# STM32G031C4T6 register map
File version: 1.0
Registers are 32-bit, access not given, reset 0x0 unless marked. A register's access mark holds for its fields unless they carry their own. Offsets are from the block's base; [hi:lo] are bit positions; {n}, {i} and the like mark numbered series.

## I2C1
Base 0x40005400
Same registers: I2C2 0x40005800, I2C3 0x40008800
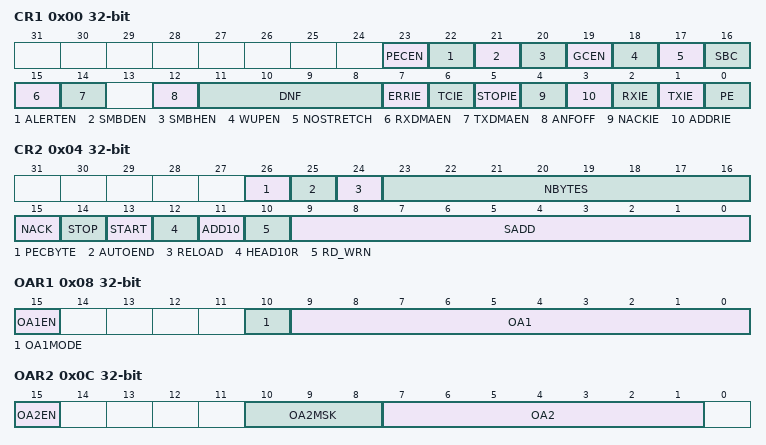
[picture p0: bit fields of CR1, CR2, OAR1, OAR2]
0x00 CR1
  [23] PECEN, [22] ALERTEN, [21] SMBDEN, [20] SMBHEN, [19] GCEN, [18] WUPEN, [17] NOSTRETCH, [16] SBC, [15] RXDMAEN, [14] TXDMAEN, [12] ANFOFF, [11:8] DNF, [7] ERRIE, [6] TCIE, [5] STOPIE, [4] NACKIE, [3] ADDRIE, [2] RXIE, [1] TXIE, [0] PE
0x04 CR2
  [26] PECBYTE, [25] AUTOEND, [24] RELOAD, [23:16] NBYTES, [15] NACK, [14] STOP, [13] START, [12] HEAD10R, [11] ADD10, [10] RD_WRN, [9:0] SADD
0x08 OAR1
  [15] OA1EN, [10] OA1MODE, [9:0] OA1
0x0C OAR2
  [15] OA2EN, [10:8] OA2MSK, [7:1] OA2
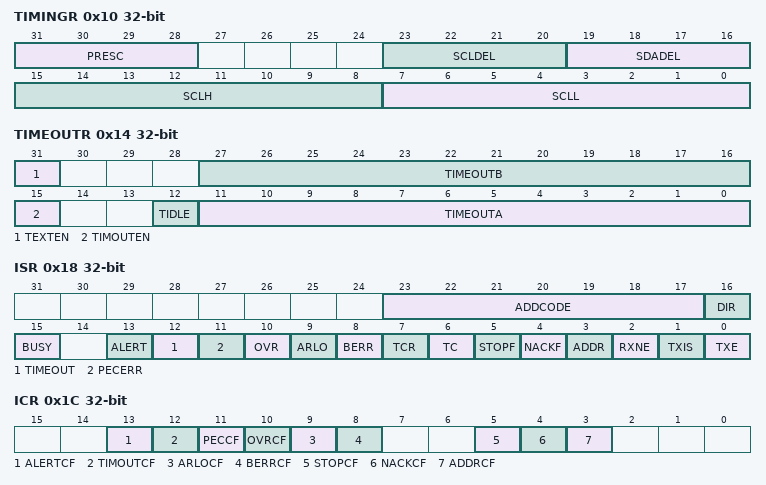
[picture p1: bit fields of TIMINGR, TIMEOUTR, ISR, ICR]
0x10 TIMINGR
  [31:28] PRESC, [23:20] SCLDEL, [19:16] SDADEL, [15:8] SCLH, [7:0] SCLL
0x14 TIMEOUTR
  [31] TEXTEN, [27:16] TIMEOUTB, [15] TIMOUTEN, [12] TIDLE, [11:0] TIMEOUTA
0x18 ISR
  [23:17] ADDCODE, [16] DIR, [15] BUSY, [13] ALERT, [12] TIMEOUT, [11] PECERR, [10] OVR, [9] ARLO, [8] BERR, [7] TCR, [6] TC, [5] STOPF, [4] NACKF, [3] ADDR, [2] RXNE, [1] TXIS, [0] TXE
0x1C ICR
  [13] ALERTCF, [12] TIMOUTCF, [11] PECCF, [10] OVRCF, [9] ARLOCF, [8] BERRCF, [5] STOPCF, [4] NACKCF, [3] ADDRCF
0x20 PECR
  [7:0] PEC
0x24 RXDR
  [7:0] RXDATA
0x28 TXDR
  [7:0] TXDATA

## USB
Base 0x40005C00
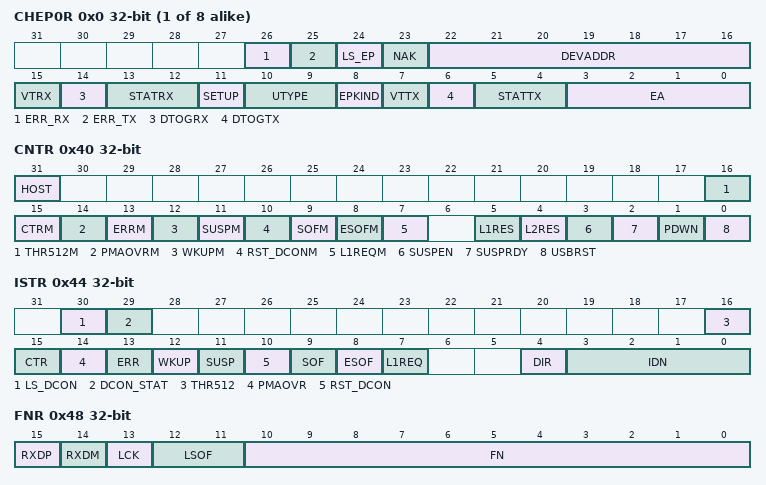
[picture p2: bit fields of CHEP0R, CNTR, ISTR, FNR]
{0x0+4i} CHEP{i}R (i=0..7)
  [26] ERR_RX, [25] ERR_TX, [24] LS_EP, [23] NAK, [22:16] DEVADDR, [15] VTRX, [14] DTOGRX, [13:12] STATRX, [11] SETUP, [10:9] UTYPE, [8] EPKIND, [7] VTTX, [6] DTOGTX, [5:4] STATTX, [3:0] EA
0x40 CNTR
  [31] HOST, [16] THR512M, [15] CTRM, [14] PMAOVRM, [13] ERRM, [12] WKUPM, [11] SUSPM, [10] RST_DCONM, [9] SOFM, [8] ESOFM, [7] L1REQM, [5] L1RES, [4] L2RES, [3] SUSPEN, [2] SUSPRDY, [1] PDWN, [0] USBRST
0x44 ISTR
  [30] LS_DCON, [29] DCON_STAT, [16] THR512, [15] CTR, [14] PMAOVR, [13] ERR, [12] WKUP, [11] SUSP, [10] RST_DCON, [9] SOF, [8] ESOF, [7] L1REQ, [4] DIR, [3:0] IDN
0x48 FNR
  [15] RXDP, [14] RXDM, [13] LCK, [12:11] LSOF, [10:0] FN
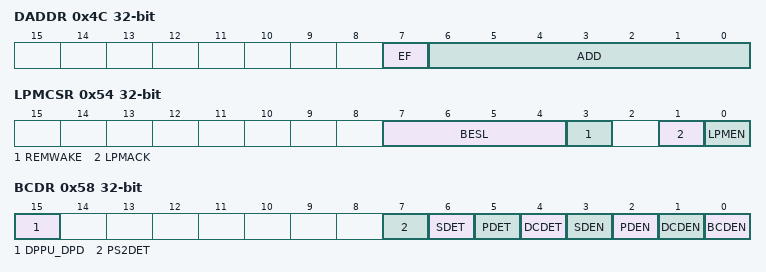
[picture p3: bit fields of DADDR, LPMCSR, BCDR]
0x4C DADDR
  [7] EF, [6:0] ADD
0x54 LPMCSR
  [7:4] BESL, [3] REMWAKE, [1] LPMACK, [0] LPMEN
0x58 BCDR
  [15] DPPU_DPD, [7] PS2DET, [6] SDET, [5] PDET, [4] DCDET, [3] SDEN, [2] PDEN, [1] DCDEN, [0] BCDEN

## FDCAN1
Base 0x40006400
Same registers: FDCAN2 0x40006800
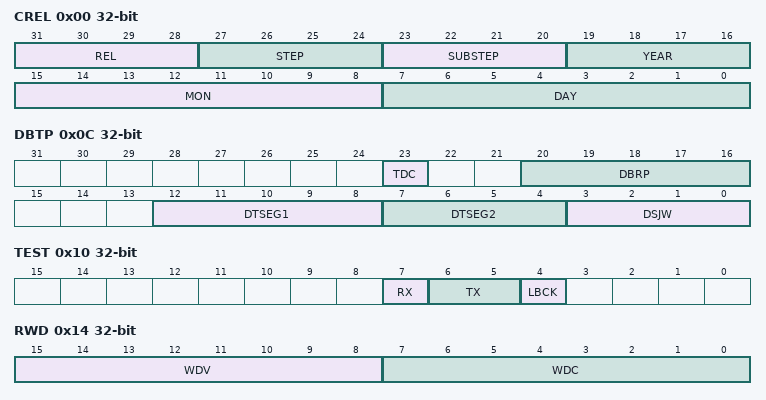
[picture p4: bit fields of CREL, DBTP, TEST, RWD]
0x00 CREL
  [31:28] REL, [27:24] STEP, [23:20] SUBSTEP, [19:16] YEAR, [15:8] MON, [7:0] DAY
0x04 ENDN
  [31:0] ETV
0x0C DBTP
  [23] TDC, [20:16] DBRP, [12:8] DTSEG1, [7:4] DTSEG2, [3:0] DSJW
0x10 TEST
  [7] RX, [6:5] TX, [4] LBCK
0x14 RWD
  [15:8] WDV, [7:0] WDC
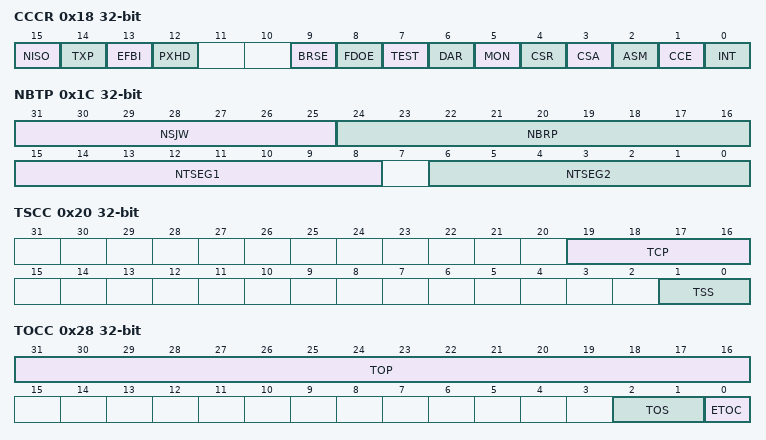
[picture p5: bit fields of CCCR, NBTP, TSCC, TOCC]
0x18 CCCR
  [15] NISO, [14] TXP, [13] EFBI, [12] PXHD, [9] BRSE, [8] FDOE, [7] TEST, [6] DAR, [5] MON, [4] CSR, [3] CSA, [2] ASM, [1] CCE, [0] INT
0x1C NBTP
  [31:25] NSJW, [24:16] NBRP, [15:8] NTSEG1, [6:0] NTSEG2
0x20 TSCC
  [19:16] TCP, [1:0] TSS
0x24 TSCV
  [15:0] TSC
0x28 TOCC
  [31:16] TOP, [2:1] TOS, [0] ETOC
0x2C TOCV
  [15:0] TOC
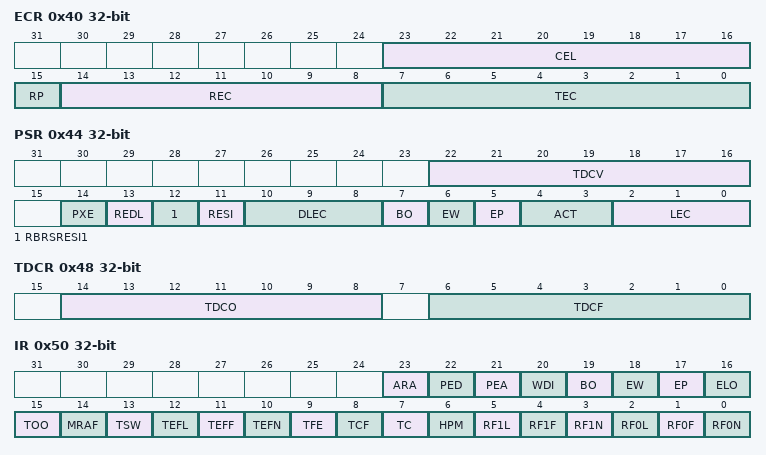
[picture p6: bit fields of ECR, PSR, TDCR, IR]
0x40 ECR
  [23:16] CEL, [15] RP, [14:8] REC, [7:0] TEC
0x44 PSR
  [22:16] TDCV, [14] PXE, [13] REDL, [12] RBRSRESI1, [11] RESI, [10:8] DLEC, [7] BO, [6] EW, [5] EP, [4:3] ACT, [2:0] LEC
0x48 TDCR
  [14:8] TDCO, [6:0] TDCF
0x50 IR
  [23] ARA, [22] PED, [21] PEA, [20] WDI, [19] BO, [18] EW, [17] EP, [16] ELO, [15] TOO, [14] MRAF, [13] TSW, [12] TEFL, [11] TEFF, [10] TEFN, [9] TFE, [8] TCF, [7] TC, [6] HPM, [5] RF1L, [4] RF1F, [3] RF1N, [2] RF0L, [1] RF0F, [0] RF0N
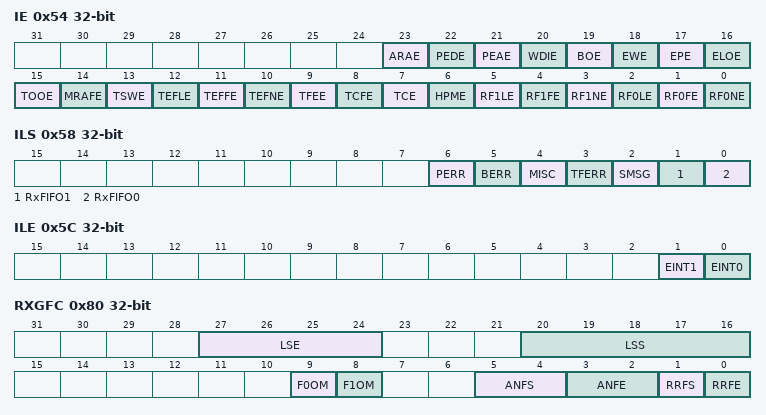
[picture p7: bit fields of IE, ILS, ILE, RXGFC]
0x54 IE
  [23] ARAE, [22] PEDE, [21] PEAE, [20] WDIE, [19] BOE, [18] EWE, [17] EPE, [16] ELOE, [15] TOOE, [14] MRAFE, [13] TSWE, [12] TEFLE, [11] TEFFE, [10] TEFNE, [9] TFEE, [8] TCFE, [7] TCE, [6] HPME, [5] RF1LE, [4] RF1FE, [3] RF1NE, [2] RF0LE, [1] RF0FE, [0] RF0NE
0x58 ILS
  [6] PERR, [5] BERR, [4] MISC, [3] TFERR, [2] SMSG, [1] RxFIFO1, [0] RxFIFO0
0x5C ILE
  [1] EINT1, [0] EINT0
0x80 RXGFC
  [27:24] LSE, [20:16] LSS, [9] F0OM, [8] F1OM, [5:4] ANFS, [3:2] ANFE, [1] RRFS, [0] RRFE
0x84 XIDAM
  [28:0] EIDM
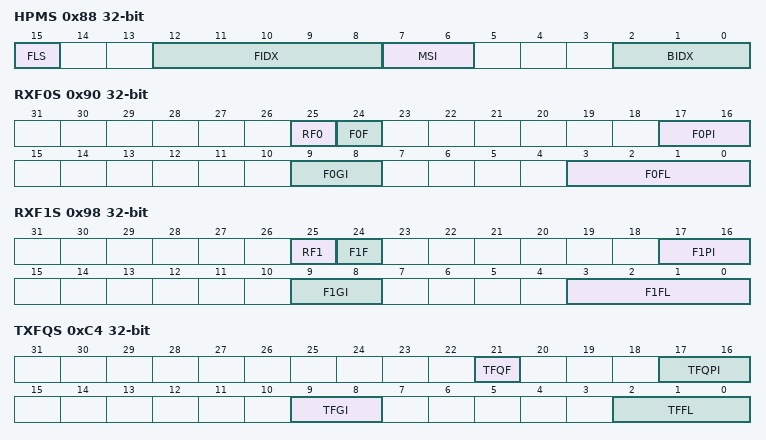
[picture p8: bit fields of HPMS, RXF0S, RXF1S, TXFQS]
0x88 HPMS
  [15] FLS, [12:8] FIDX, [7:6] MSI, [2:0] BIDX
0x90 RXF0S
  [25] RF0, [24] F0F, [17:16] F0PI, [9:8] F0GI, [3:0] F0FL
0x94 RXF0A
  [2:0] F0AI
0x98 RXF1S
  [25] RF1, [24] F1F, [17:16] F1PI, [9:8] F1GI, [3:0] F1FL
0x9C RXF1A
  [2:0] F1AI
0xC0 TXBC
  [24] TFQM
0xC4 TXFQS
  [21] TFQF, [17:16] TFQPI, [9:8] TFGI, [2:0] TFFL
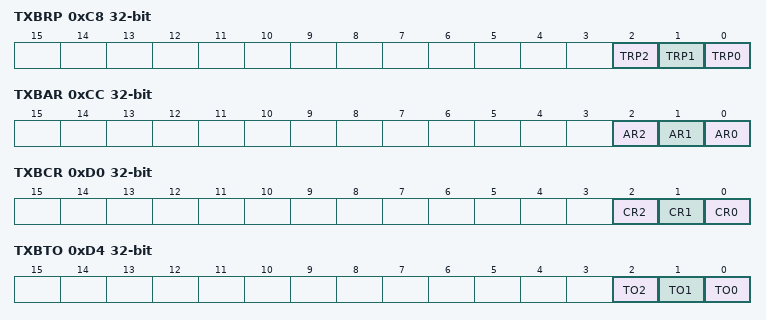
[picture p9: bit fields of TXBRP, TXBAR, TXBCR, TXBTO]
0xC8 TXBRP
  [2] TRP2, [1] TRP1, [0] TRP0
0xCC TXBAR
  [2] AR2, [1] AR1, [0] AR0
0xD0 TXBCR
  [2] CR2, [1] CR1, [0] CR0
0xD4 TXBTO
  [2] TO2, [1] TO1, [0] TO0
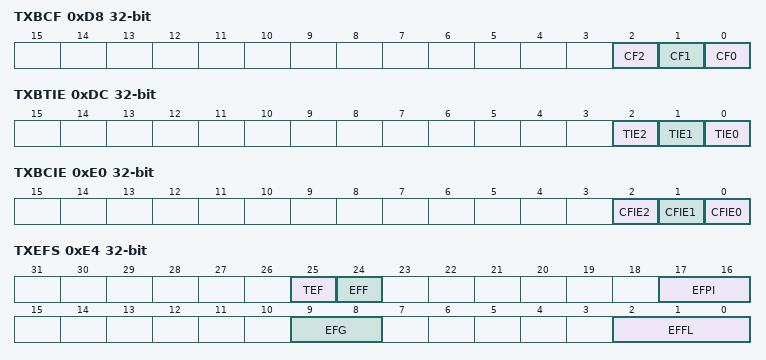
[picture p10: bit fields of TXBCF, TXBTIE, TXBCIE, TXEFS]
0xD8 TXBCF
  [2] CF2, [1] CF1, [0] CF0
0xDC TXBTIE
  [2] TIE2, [1] TIE1, [0] TIE0
0xE0 TXBCIE
  [2] CFIE2, [1] CFIE1, [0] CFIE0
0xE4 TXEFS
  [25] TEF, [24] EFF, [17:16] EFPI, [9:8] EFG, [2:0] EFFL
0xE8 TXEFA
  [1:0] EFAI
0x100 CKDIV
  [3:0] PDIV
